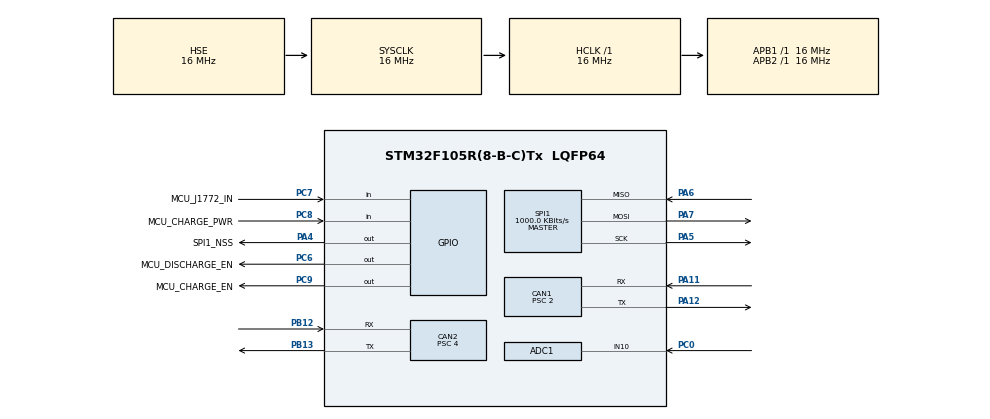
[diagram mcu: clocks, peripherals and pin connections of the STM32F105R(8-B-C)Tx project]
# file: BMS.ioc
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ADC1.Channel-0\#ChannelRegularConversion=ADC_CHANNEL_10
ADC1.NbrOfConversionFlag=1
ADC1.Rank-0\#ChannelRegularConversion=1
ADC1.SamplingTime-0\#ChannelRegularConversion=ADC_SAMPLETIME_1CYCLE_5
ADC1.master=1
CAN1.ABOM=ENABLE
CAN1.AWUM=ENABLE
CAN1.BS1=CAN_BS1_13TQ
CAN1.BS2=CAN_BS2_2TQ
CAN1.CalculateBaudRate=500000
CAN1.CalculateTimeBit=2000
CAN1.CalculateTimeQuantum=125.0
CAN1.NART=ENABLE
CAN1.Prescaler=2
CAN2.ABOM=ENABLE
CAN2.AWUM=ENABLE
CAN2.BS1=CAN_BS1_13TQ
CAN2.BS2=CAN_BS2_2TQ
CAN2.CalculateBaudRate=250000
CAN2.CalculateTimeBit=4000
CAN2.CalculateTimeQuantum=250.0
CAN2.NART=ENABLE
CAN2.Prescaler=4
Mcu.Family=STM32F1
Mcu.Name=STM32F105R(8-B-C)Tx
Mcu.Package=LQFP64
NVIC.CAN1_RX0_IRQn=true\:0\:0\:false\:false\:true\:true\:true\:true
NVIC.CAN2_RX0_IRQn=true\:0\:0\:false\:false\:true\:true\:true\:true
NVIC.CAN2_TX_IRQn=true\:0\:0\:false\:false\:true\:true\:true\:true
NVIC.PriorityGroup=NVIC_PRIORITYGROUP_4
PA11.Mode=CAN_Activate
PA11.Signal=CAN1_RX
PA12.Mode=CAN_Activate
PA12.Signal=CAN1_TX
PA13.Mode=Trace_Asynchronous_SW
PA13.Signal=SYS_JTMS-SWDIO
PA14.Mode=Trace_Asynchronous_SW
PA14.Signal=SYS_JTCK-SWCLK
PA4.GPIO_Label=SPI1_NSS
PA4.GPIO_PuPd=GPIO_NOPULL
PA4.PinState=GPIO_PIN_SET
PA4.Signal=GPIO_Output
PA5.Mode=Full_Duplex_Master
PA5.Signal=SPI1_SCK
PA6.Mode=Full_Duplex_Master
PA6.Signal=SPI1_MISO
PA7.Mode=Full_Duplex_Master
PA7.Signal=SPI1_MOSI
PB12.Mode=CAN_Activate
PB12.Signal=CAN2_RX
PB13.Mode=CAN_Activate
PB13.Signal=CAN2_TX
PB3.Mode=Trace_Asynchronous_SW
PB3.Signal=SYS_TRACESWO
PC0.Signal=ADCx_IN10
PC6.GPIO_Label=MCU_DISCHARGE_EN
PC6.Signal=GPIO_Output
PC7.GPIO_Label=MCU_J1772_IN
PC7.Signal=GPIO_Input
PC8.GPIO_Label=MCU_CHARGE_PWR
PC8.Signal=GPIO_Input
PC9.GPIO_Label=MCU_CHARGE_EN
PC9.Signal=GPIO_Output
PD0-OSC_IN.Mode=HSE-External-Oscillator
PD0-OSC_IN.Signal=RCC_OSC_IN
PD1-OSC_OUT.Mode=HSE-External-Oscillator
PD1-OSC_OUT.Signal=RCC_OSC_OUT
ProjectManager.HeapSize=0x200
ProjectManager.StackSize=0x400
ProjectManager.TargetToolchain=STM32CubeIDE
RCC.AHBFreq_Value=16000000
RCC.APB1Freq_Value=16000000
RCC.APB1TimFreq_Value=16000000
RCC.APB2Freq_Value=16000000
RCC.APB2TimFreq_Value=16000000
RCC.HCLKFreq_Value=16000000
RCC.HSE_VALUE=16000000
RCC.PLLSourceVirtual=RCC_PLLSOURCE_HSE
RCC.SYSCLKFreq_VALUE=16000000
RCC.SYSCLKSource=RCC_SYSCLKSOURCE_HSE
RCC.USBFreq_Value=42666666.666666664
SH.ADCx_IN10.0=ADC1_IN10,IN10
SPI1.BaudRatePrescaler=SPI_BAUDRATEPRESCALER_16
SPI1.CalculateBaudRate=1000.0 KBits/s
SPI1.DataSize=SPI_DATASIZE_8BIT
SPI1.Direction=SPI_DIRECTION_2LINES
SPI1.Mode=SPI_MODE_MASTER
SPI1.VirtualType=VM_MASTER
board=custom

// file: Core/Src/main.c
/* USER CODE BEGIN Header */
/**
  ******************************************************************************
  * @file           : main.c
  * @brief          : Main program body
  ******************************************************************************
  * @attention
  *
  * Copyright (c) 2026 STMicroelectronics.
  * All rights reserved.
  *
  * This software is licensed under terms that can be found in the LICENSE file
  * in the root directory of this software component.
  * If no LICENSE file comes with this software, it is provided AS-IS.
  *
  ******************************************************************************
  */
/* USER CODE END Header */
#include "main.h"

/* USER CODE BEGIN Includes */
#include "bms_monitor.h"
/* USER CODE END Includes */

ADC_HandleTypeDef hadc1;

CAN_HandleTypeDef hcan1;
CAN_HandleTypeDef hcan2;

SPI_HandleTypeDef hspi1;

void SystemClock_Config(void);
static void MX_GPIO_Init(void);
static void MX_ADC1_Init(void);
static void MX_CAN1_Init(void);
static void MX_CAN2_Init(void);
static void MX_SPI1_Init(void);

int main(void)
{

  /* MCU Configuration--------------------------------------------------------*/

  /* Reset of all peripherals, Initializes the Flash interface and the Systick. */
  HAL_Init();

  /* Configure the system clock */
  SystemClock_Config();

  /* Initialize all configured peripherals */
  MX_GPIO_Init();
  MX_ADC1_Init();
  MX_CAN1_Init();
  MX_CAN2_Init();
  MX_SPI1_Init();
  /* USER CODE BEGIN 2 */
  bms_monitor_init();
  /* USER CODE END 2 */

  /* Infinite loop */
  while (1)
  {

    /* USER CODE BEGIN 3 */
    bms_monitor_run();
  }
  /* USER CODE END 3 */
}

void SystemClock_Config(void)
{
  RCC_OscInitTypeDef RCC_OscInitStruct = {0};
  RCC_ClkInitTypeDef RCC_ClkInitStruct = {0};
  RCC_PeriphCLKInitTypeDef PeriphClkInit = {0};

  /** Initializes the RCC Oscillators according to the specified parameters
  * in the RCC_OscInitTypeDef structure.
  */
  RCC_OscInitStruct.OscillatorType = RCC_OSCILLATORTYPE_HSE;
  RCC_OscInitStruct.HSEState = RCC_HSE_ON;
  RCC_OscInitStruct.PLL.PLLState = RCC_PLL_NONE;
  RCC_OscInitStruct.PLL2.PLL2State = RCC_PLL_NONE;
  if (HAL_RCC_OscConfig(&RCC_OscInitStruct) != HAL_OK)
  {
    Error_Handler();
  }

  /** Initializes the CPU, AHB and APB buses clocks
  */
  RCC_ClkInitStruct.ClockType = RCC_CLOCKTYPE_HCLK|RCC_CLOCKTYPE_SYSCLK
                              |RCC_CLOCKTYPE_PCLK1|RCC_CLOCKTYPE_PCLK2;
  RCC_ClkInitStruct.SYSCLKSource = RCC_SYSCLKSOURCE_HSE;
  RCC_ClkInitStruct.AHBCLKDivider = RCC_SYSCLK_DIV1;
  RCC_ClkInitStruct.APB1CLKDivider = RCC_HCLK_DIV1;
  RCC_ClkInitStruct.APB2CLKDivider = RCC_HCLK_DIV1;

  if (HAL_RCC_ClockConfig(&RCC_ClkInitStruct, FLASH_LATENCY_0) != HAL_OK)
  {
    Error_Handler();
  }
  PeriphClkInit.PeriphClockSelection = RCC_PERIPHCLK_ADC;
  PeriphClkInit.AdcClockSelection = RCC_ADCPCLK2_DIV2;
  if (HAL_RCCEx_PeriphCLKConfig(&PeriphClkInit) != HAL_OK)
  {
    Error_Handler();
  }

  /** Configure the Systick interrupt time
  */
  __HAL_RCC_PLLI2S_ENABLE();
}

static void MX_ADC1_Init(void)
{

  ADC_ChannelConfTypeDef sConfig = {0};

  /** Common config
  */
  hadc1.Instance = ADC1;
  hadc1.Init.ScanConvMode = ADC_SCAN_DISABLE;
  hadc1.Init.ContinuousConvMode = DISABLE;
  hadc1.Init.DiscontinuousConvMode = DISABLE;
  hadc1.Init.ExternalTrigConv = ADC_SOFTWARE_START;
  hadc1.Init.DataAlign = ADC_DATAALIGN_RIGHT;
  hadc1.Init.NbrOfConversion = 1;
  if (HAL_ADC_Init(&hadc1) != HAL_OK)
  {
    Error_Handler();
  }

  /** Configure Regular Channel
  */
  sConfig.Channel = ADC_CHANNEL_10;
  sConfig.Rank = ADC_REGULAR_RANK_1;
  sConfig.SamplingTime = ADC_SAMPLETIME_1CYCLE_5;
  if (HAL_ADC_ConfigChannel(&hadc1, &sConfig) != HAL_OK)
  {
    Error_Handler();
  }

}

static void MX_CAN1_Init(void)
{

  hcan1.Instance = CAN1;
  hcan1.Init.Prescaler = 2;
  hcan1.Init.Mode = CAN_MODE_NORMAL;
  hcan1.Init.SyncJumpWidth = CAN_SJW_1TQ;
  hcan1.Init.TimeSeg1 = CAN_BS1_13TQ;
  hcan1.Init.TimeSeg2 = CAN_BS2_2TQ;
  hcan1.Init.TimeTriggeredMode = DISABLE;
  hcan1.Init.AutoBusOff = ENABLE;
  hcan1.Init.AutoWakeUp = ENABLE;
  hcan1.Init.AutoRetransmission = ENABLE;
  hcan1.Init.ReceiveFifoLocked = DISABLE;
  hcan1.Init.TransmitFifoPriority = DISABLE;
  if (HAL_CAN_Init(&hcan1) != HAL_OK)
  {
    Error_Handler();
  }

}

static void MX_CAN2_Init(void)
{

  hcan2.Instance = CAN2;
  hcan2.Init.Prescaler = 4;
  hcan2.Init.Mode = CAN_MODE_NORMAL;
  hcan2.Init.SyncJumpWidth = CAN_SJW_1TQ;
  hcan2.Init.TimeSeg1 = CAN_BS1_13TQ;
  hcan2.Init.TimeSeg2 = CAN_BS2_2TQ;
  hcan2.Init.TimeTriggeredMode = DISABLE;
  hcan2.Init.AutoBusOff = ENABLE;
  hcan2.Init.AutoWakeUp = ENABLE;
  hcan2.Init.AutoRetransmission = ENABLE;
  hcan2.Init.ReceiveFifoLocked = DISABLE;
  hcan2.Init.TransmitFifoPriority = DISABLE;
  if (HAL_CAN_Init(&hcan2) != HAL_OK)
  {
    Error_Handler();
  }

}

static void MX_SPI1_Init(void)
{

  /* SPI1 parameter configuration*/
  hspi1.Instance = SPI1;
  hspi1.Init.Mode = SPI_MODE_MASTER;
  hspi1.Init.Direction = SPI_DIRECTION_2LINES;
  hspi1.Init.DataSize = SPI_DATASIZE_8BIT;
  hspi1.Init.CLKPolarity = SPI_POLARITY_LOW;
  hspi1.Init.CLKPhase = SPI_PHASE_1EDGE;
  hspi1.Init.NSS = SPI_NSS_SOFT;
  hspi1.Init.BaudRatePrescaler = SPI_BAUDRATEPRESCALER_16;
  hspi1.Init.FirstBit = SPI_FIRSTBIT_MSB;
  hspi1.Init.TIMode = SPI_TIMODE_DISABLE;
  hspi1.Init.CRCCalculation = SPI_CRCCALCULATION_DISABLE;
  hspi1.Init.CRCPolynomial = 10;
  if (HAL_SPI_Init(&hspi1) != HAL_OK)
  {
    Error_Handler();
  }

}

static void MX_GPIO_Init(void)
{
  GPIO_InitTypeDef GPIO_InitStruct = {0};

  /* GPIO Ports Clock Enable */
  __HAL_RCC_GPIOD_CLK_ENABLE();
  __HAL_RCC_GPIOC_CLK_ENABLE();
  __HAL_RCC_GPIOA_CLK_ENABLE();
  __HAL_RCC_GPIOB_CLK_ENABLE();

  /*Configure GPIO pin Output Level */
  HAL_GPIO_WritePin(SPI1_NSS_GPIO_Port, SPI1_NSS_Pin, GPIO_PIN_SET);

  /*Configure GPIO pin Output Level */
  HAL_GPIO_WritePin(GPIOC, MCU_DISCHARGE_EN_Pin|MCU_CHARGE_EN_Pin, GPIO_PIN_RESET);

  /*Configure GPIO pin : SPI1_NSS_Pin */
  GPIO_InitStruct.Pin = SPI1_NSS_Pin;
  GPIO_InitStruct.Mode = GPIO_MODE_OUTPUT_PP;
  GPIO_InitStruct.Pull = GPIO_NOPULL;
  GPIO_InitStruct.Speed = GPIO_SPEED_FREQ_LOW;
  HAL_GPIO_Init(SPI1_NSS_GPIO_Port, &GPIO_InitStruct);

  /*Configure GPIO pins : MCU_DISCHARGE_EN_Pin MCU_CHARGE_EN_Pin */
  GPIO_InitStruct.Pin = MCU_DISCHARGE_EN_Pin|MCU_CHARGE_EN_Pin;
  GPIO_InitStruct.Mode = GPIO_MODE_OUTPUT_PP;
  GPIO_InitStruct.Pull = GPIO_NOPULL;
  GPIO_InitStruct.Speed = GPIO_SPEED_FREQ_LOW;
  HAL_GPIO_Init(GPIOC, &GPIO_InitStruct);

  /*Configure GPIO pins : MCU_J1772_IN_Pin MCU_CHARGE_PWR_Pin */
  GPIO_InitStruct.Pin = MCU_J1772_IN_Pin|MCU_CHARGE_PWR_Pin;
  GPIO_InitStruct.Mode = GPIO_MODE_INPUT;
  GPIO_InitStruct.Pull = GPIO_NOPULL;
  HAL_GPIO_Init(GPIOC, &GPIO_InitStruct);

}

void Error_Handler(void)
{
  __disable_irq();
  while (1)
  {
  }
}
